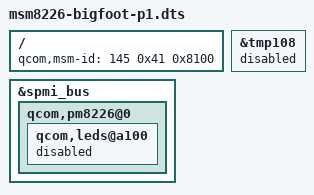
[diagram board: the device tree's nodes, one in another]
/* Copyright (c) 2013, Motorola Mobility LLC
 *
 * This program is free software; you can redistribute it and/or modify
 * it under the terms of the GNU General Public License version 2 and
 * only version 2 as published by the Free Software Foundation.
 *
 * This program is distributed in the hope that it will be useful,
 * but WITHOUT ANY WARRANTY; without even the implied warranty of
 * MERCHANTABILITY or FITNESS FOR A PARTICULAR PURPOSE.  See the
 * GNU General Public License for more details.
 */

/dts-v1/;

/include/ "msm8226-moto-reserve.dtsi"
/include/ "msm8226-v1.dtsi"
/include/ "msm8226-bigfoot-common.dtsi"

/ {
	qcom,msm-id = <145 0x41 0x8100>;
};

&tmp108 {
	status = "disabled";
};

&spmi_bus {
	qcom,pm8226@0 {
		qcom,leds@a100 {
			status = "disabled";
		};
	};
};
